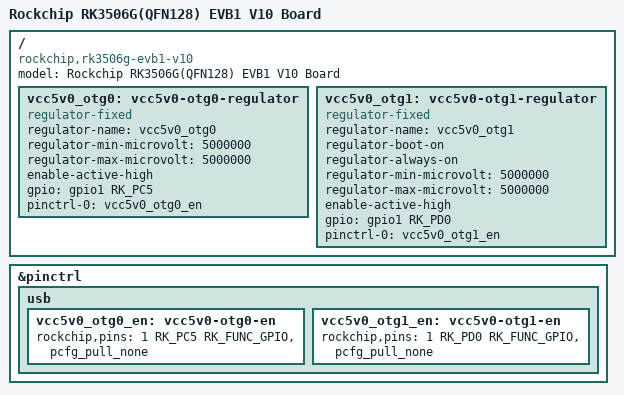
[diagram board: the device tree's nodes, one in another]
// SPDX-License-Identifier: (GPL-2.0+ OR MIT)
/*
 * Copyright (c) 2024 Rockchip Electronics Co., Ltd.
 */

/dts-v1/;

#include "rk3506.dtsi"
#include "rk3506-evb1-v10.dtsi"

/ {
	model = "Rockchip RK3506G(QFN128) EVB1 V10 Board";
	compatible = "rockchip,rk3506g-evb1-v10", "rockchip,rk3506";

	vcc5v0_otg0: vcc5v0-otg0-regulator {
		compatible = "regulator-fixed";
		regulator-name = "vcc5v0_otg0";
		regulator-min-microvolt = <5000000>;
		regulator-max-microvolt = <5000000>;
		enable-active-high;
		gpio = <&gpio1 RK_PC5 GPIO_ACTIVE_HIGH>;
		pinctrl-names = "default";
		pinctrl-0 = <&vcc5v0_otg0_en>;
	};

	vcc5v0_otg1: vcc5v0-otg1-regulator {
		compatible = "regulator-fixed";
		regulator-name = "vcc5v0_otg1";
		regulator-boot-on;
		regulator-always-on;
		regulator-min-microvolt = <5000000>;
		regulator-max-microvolt = <5000000>;
		enable-active-high;
		gpio = <&gpio1 RK_PD0 GPIO_ACTIVE_HIGH>;
		pinctrl-names = "default";
		pinctrl-0 = <&vcc5v0_otg1_en>;
	};
};

&pinctrl {
	usb {
		vcc5v0_otg0_en: vcc5v0-otg0-en {
			rockchip,pins = <1 RK_PC5 RK_FUNC_GPIO &pcfg_pull_none>;
		};

		vcc5v0_otg1_en: vcc5v0-otg1-en {
			rockchip,pins = <1 RK_PD0 RK_FUNC_GPIO &pcfg_pull_none>;
		};
	};
};
